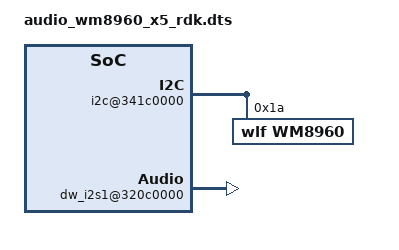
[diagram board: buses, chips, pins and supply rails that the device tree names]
/dts-v1/;
/plugin/;

/ {
  fragment@0 {
    target-path = "/soc/a55_apb0/i2c@341c0000";
    __overlay__ {
        wm8960:wm8960@1a{
            compatible = "wlf,wm8960";
            reg = <0x1a>;
            #sound-dai-cells = <0>;
            status = "okay";
        };
    };
  };
  fragment@1 {
    target-path = "/soc/dsp_apb/dw_i2s1@320c0000";
    __overlay__ {
      status = "okay";
      dwc-master = <1>;
    };
  };
  fragment@2 {
    target-path = "/hobot_sound_machine";
    __overlay__ {
        status = "okay";
        #address-cells = <1>;
        #size-cells = <0>;
        simple-audio-card,name = "duplex-audio-i2s1";

        simple-audio-card,dai-link@0 {
            link-name = "dai-link0";
            reg = <0>;
            format = "i2s";
            bitclock-master = <&snd1_mm>;
            frame-master = <&snd1_mm>;
            snd1_mm: cpu {
                sound-dai = <&dw_i2s1 1>;
            };
            codec {
                sound-dai = <&wm8960>;
            };
        };
    };
  };
};


